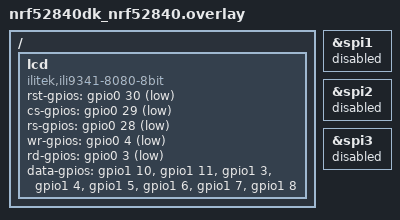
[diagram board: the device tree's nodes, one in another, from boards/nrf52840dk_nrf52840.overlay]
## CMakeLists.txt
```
cmake_minimum_required(VERSION 3.20.0)
find_package(Zephyr REQUIRED HINTS $ENV{ZEPHYR_BASE})

project(ili9341shield)

target_sources(app PRIVATE src/main.c)

# Add the ili9341 library source file
target_sources(app PRIVATE src/lib/ili9341.c)
target_sources(app PRIVATE src/lib/font.c)

target_include_directories(app PRIVATE src/lib)
```

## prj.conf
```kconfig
CONFIG_LOG=y
CONFIG_GPIO=y
```

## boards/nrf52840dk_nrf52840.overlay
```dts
/{ 
    lcd {
        compatible = "ilitek,ili9341-8080-8bit";
        status = "okay";

        rst-gpios = <&gpio0 30 GPIO_ACTIVE_LOW>;     // LCD_RST reset
        cs-gpios = <&gpio0 29 GPIO_ACTIVE_LOW>;      // LCD_CS chip select
        rs-gpios = <&gpio0 28 GPIO_ACTIVE_LOW>;     // LCD_RS register set (1 = data, 0 = command)
        wr-gpios = <&gpio0 4 GPIO_ACTIVE_LOW>;      // LCD_WR write
        rd-gpios = <&gpio0 3 GPIO_ACTIVE_LOW>;      // LCD_RD read

        data-gpios = <&gpio1 10 GPIO_ACTIVE_HIGH>, // LCD Data Bit 0
                    <&gpio1 11 GPIO_ACTIVE_HIGH>,  // LCD Data Bit 1
                    <&gpio1 3 GPIO_ACTIVE_HIGH>,   // LCD Data Bit 2
                    <&gpio1 4 GPIO_ACTIVE_HIGH>,   // LCD Data Bit 3
                    <&gpio1 5 GPIO_ACTIVE_HIGH>,   // LCD Data Bit 4
                    <&gpio1 6 GPIO_ACTIVE_HIGH>,   // LCD Data Bit 5
                    <&gpio1 7 GPIO_ACTIVE_HIGH>,   // LCD Data Bit 6
                    <&gpio1 8 GPIO_ACTIVE_HIGH>;   // LCD Data Bit 7
    };
};

&spi1 {
    status = "disabled";
};

&spi2 {
    status = "disabled";
};

&spi3 {
    status = "disabled";
};
```

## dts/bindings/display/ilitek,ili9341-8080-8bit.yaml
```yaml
description: Binding for the ILI9341-based LCD module (8080 8bit interface)

compatible: "ilitek,ili9341-8080-8bit"

properties:
  rst-gpios:
    type: phandle-array
    required: true
    description: GPIO specifier for the LCD_RST reset pin

  cs-gpios:
    type: phandle-array
    required: true
    description: GPIO specifier for the LCD_CS chip select pin

  rs-gpios:
    type: phandle-array
    required: true
    description: GPIO specifier for the LCD_RS register select (data/command) pin

  wr-gpios:
    type: phandle-array
    required: true
    description: GPIO specifier for the LCD_WR write signal pin

  rd-gpios:
    type: phandle-array
    required: true
    description: GPIO specifier for the LCD_RD read signal pin

  data-gpios:
    type: phandle-array
    required: true
    description: GPIO specifier array for the LCD data pins (8-bit bus)
```

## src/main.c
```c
#include <zephyr/kernel.h>
#include <zephyr/device.h>
#include <zephyr/devicetree.h>
#include <zephyr/drivers/gpio.h>
#include <zephyr/logging/log.h>
#include "lib/ili9341.h"
// #include "constants.h"

LOG_MODULE_REGISTER(lcd);

/**
 * @desc    Main function
 *
 * @param   Void
 *
 * @return  Void
 */
int main(void)
{
  // init lcd
  ILI9341_Init();

  // clear Screen
  ILI9341_ClearScreen(ILI9341_BLACK);

  // draw horizontal fast line
  ILI9341_DrawLineHorizontal(10, ILI9341_MAX_X - 10, 12, ILI9341_WHITE);
  // draw horizontal fast line
  ILI9341_DrawLineHorizontal(10, ILI9341_MAX_X - 10, 50, ILI9341_WHITE);

  // set position
  ILI9341_SetPosition(11, 25);  
  // draw string
  ILI9341_DrawString("ILI9341 LCD DRIVER", ILI9341_RED, X3);

  // EXIT
  // ------------------------------------------------- 
  // return & exit
  return 0;
}
```
